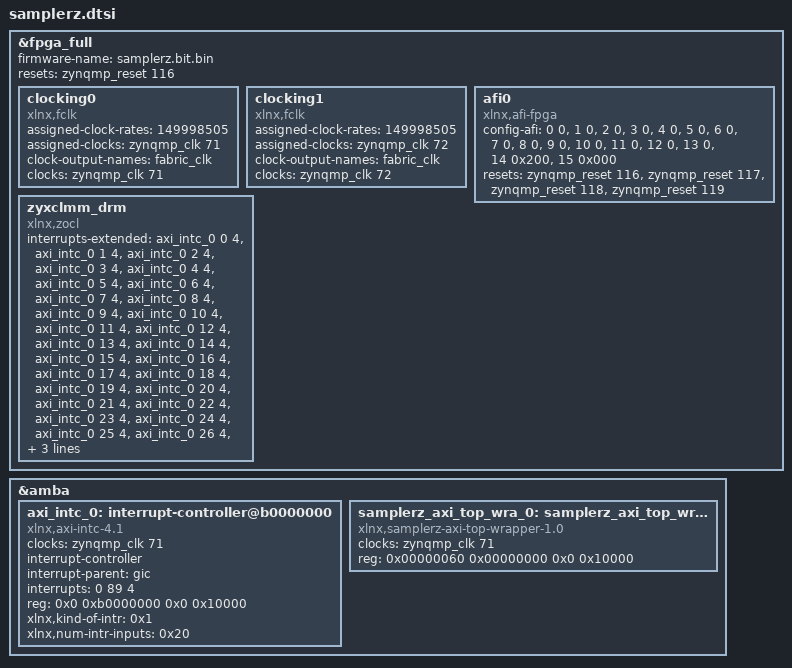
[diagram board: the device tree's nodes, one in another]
/*
 * CAUTION: This file is automatically generated by Xilinx.
 * Version: XSCT 2024.2
 * Today is: Sun May  4 19:19:48 2025
 */


/dts-v1/;
/plugin/;
&fpga_full {
	firmware-name = "samplerz.bit.bin";
	resets = <&zynqmp_reset 116>;
	clocking0: clocking0 {
		#clock-cells = <0>;
		assigned-clock-rates = <149998505>;
		assigned-clocks = <&zynqmp_clk 71>;
		clock-output-names = "fabric_clk";
		clocks = <&zynqmp_clk 71>;
		compatible = "xlnx,fclk";
	};
	clocking1: clocking1 {
		#clock-cells = <0>;
		assigned-clock-rates = <149998505>;
		assigned-clocks = <&zynqmp_clk 72>;
		clock-output-names = "fabric_clk";
		clocks = <&zynqmp_clk 72>;
		compatible = "xlnx,fclk";
	};
	afi0: afi0 {
		compatible = "xlnx,afi-fpga";
		config-afi = < 0 0>, <1 0>, <2 0>, <3 0>, <4 0>, <5 0>, <6 0>, <7 0>, <8 0>, <9 0>, <10 0>, <11 0>, <12 0>, <13 0>, <14 0x200>, <15 0x000>;
		resets = <&zynqmp_reset 116>, <&zynqmp_reset 117>, <&zynqmp_reset 118>, <&zynqmp_reset 119>;
	};
	zyxclmm_drm {
		compatible = "xlnx,zocl";
		interrupts-extended = <&axi_intc_0 0 4>, <&axi_intc_0 1 4>, <&axi_intc_0 2 4>, <&axi_intc_0 3 4>, <&axi_intc_0 4 4>, <&axi_intc_0 5 4>, <&axi_intc_0 6 4>, <&axi_intc_0 7 4>, <&axi_intc_0 8 4>, <&axi_intc_0 9 4>,
<&axi_intc_0 10 4>, <&axi_intc_0 11 4>, <&axi_intc_0 12 4>, <&axi_intc_0 13 4>, <&axi_intc_0 14 4>,
<&axi_intc_0 15 4>, <&axi_intc_0 16 4>, <&axi_intc_0 17 4>, <&axi_intc_0 18 4>, <&axi_intc_0 19 4>,
<&axi_intc_0 20 4>, <&axi_intc_0 21 4>, <&axi_intc_0 22 4>, <&axi_intc_0 23 4>, <&axi_intc_0 24 4>,
<&axi_intc_0 25 4>, <&axi_intc_0 26 4>, <&axi_intc_0 27 4>, <&axi_intc_0 28 4>, <&axi_intc_0 29 4>,
<&axi_intc_0 30 4>, <&axi_intc_0 31 4 >;
	};
};
&amba {
	#address-cells = <2>;
	#size-cells = <2>;
	axi_intc_0: interrupt-controller@b0000000 {
		#interrupt-cells = <2>;
		clock-names = "s_axi_aclk";
		clocks = <&zynqmp_clk 71>;
		compatible = "xlnx,axi-intc-4.1", "xlnx,xps-intc-1.00.a";
		interrupt-controller ;
		interrupt-names = "irq";
		interrupt-parent = <&gic>;
		interrupts = <0 89 4>;
		reg = <0x0 0xb0000000 0x0 0x10000>;
		xlnx,kind-of-intr = <0x1>;
		xlnx,num-intr-inputs = <0x20>;
	};
	samplerz_axi_top_wra_0: samplerz_axi_top_wrapper@6000000000 {
		/* This is a place holder node for a custom IP, user may need to update the entries */
		clock-names = "aclk";
		clocks = <&zynqmp_clk 71>;
		compatible = "xlnx,samplerz-axi-top-wrapper-1.0";
		reg = <0x00000060 0x00000000 0x0 0x10000>;
	};
};
